# MSP432E411Y register map
Vendor: Texas Instruments; Series: MSP432E4; File version: 3.200
CPU: CM4 r1p2, little endian, no MPU, FPU, 3 interrupt priority bits
Registers are 32-bit, read-write, no defined reset value unless marked. A register's access mark holds for its fields unless they carry their own. Offsets are from the block's base; [hi:lo] are bit positions.

## I2C0 — Register map for I2C0 peripheral
Base 0x40020000; register names take the prefix I2C0
Same registers: I2C1 0x40021000 (register names take the prefix I2C1), I2C2 0x40022000 (register names take the prefix I2C2), I2C3 0x40023000 (register names take the prefix I2C3), I2C8 0x400B8000 (register names take the prefix I2C8), I2C9 0x400B9000 (register names take the prefix I2C9), I2C4 0x400C0000 (register names take the prefix I2C4), I2C5 0x400C1000 (register names take the prefix I2C5), I2C6 0x400C2000 (register names take the prefix I2C6), I2C7 0x400C3000 (register names take the prefix I2C7)
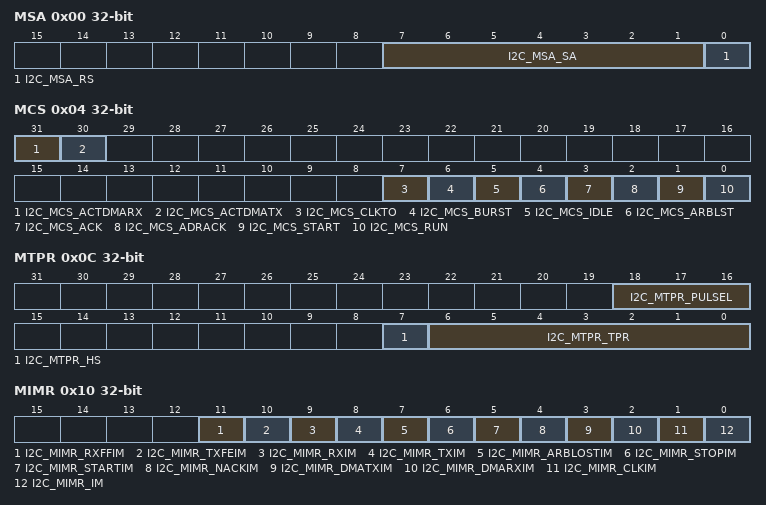
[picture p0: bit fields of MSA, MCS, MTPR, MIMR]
0x00 MSA — I2C Master Slave Address
  [7:1] I2C_MSA_SA — I2C Slave Address
  [0] I2C_MSA_RS — Receive not send
0x04 MCS — I2C Master Control/Status
  [31] I2C_MCS_ACTDMARX — DMA RX Active Status
  [30] I2C_MCS_ACTDMATX — DMA TX Active Status
  [7] I2C_MCS_CLKTO — Clock Timeout Error
  [6] I2C_MCS_BURST — Burst Enable
  [5] I2C_MCS_IDLE — I2C Idle
  [4] I2C_MCS_ARBLST — Arbitration Lost
  [3] I2C_MCS_ACK — Data Acknowledge Enable
  [2] I2C_MCS_ADRACK — Acknowledge Address
  [1] I2C_MCS_START — Generate START
  [0] I2C_MCS_RUN — I2C Master Enable
0x04 MCS (I2C0_ALT view) — I2C Master Control/Status
  [6] I2C_MCS_BUSBSY — Bus Busy
  [5] I2C_MCS_QCMD — Quick Command
  [4] I2C_MCS_HS — High-Speed Enable
  [3] I2C_MCS_DATACK — Acknowledge Data
  [2] I2C_MCS_STOP — Generate STOP
  [1] I2C_MCS_ERROR — Error
  [0] I2C_MCS_BUSY — I2C Busy
0x08 MDR — I2C Master Data
  [7:0] I2C_MDR_DATA — This byte contains the data transferred during a transaction
0x0C MTPR — I2C Master Timer Period
  [18:16] I2C_MTPR_PULSEL — Glitch Suppression Pulse Width
    0=I2C_MTPR_PULSEL_BYPASS (Bypass); 1=1 clock; 2=2 clocks; 3=3 clocks; 4=4 clocks; 5=8 clocks; 6=16 clocks; 7=31 clocks
  [7] I2C_MTPR_HS — High-Speed Enable
  [6:0] I2C_MTPR_TPR — Timer Period
0x10 MIMR — I2C Master Interrupt Mask
  [11] I2C_MIMR_RXFFIM — Receive FIFO Full Interrupt Mask
  [10] I2C_MIMR_TXFEIM — Transmit FIFO Empty Interrupt Mask
  [9] I2C_MIMR_RXIM — Receive FIFO Request Interrupt Mask
  [8] I2C_MIMR_TXIM — Transmit FIFO Request Interrupt Mask
  [7] I2C_MIMR_ARBLOSTIM — Arbitration Lost Interrupt Mask
  [6] I2C_MIMR_STOPIM — STOP Detection Interrupt Mask
  [5] I2C_MIMR_STARTIM — START Detection Interrupt Mask
  [4] I2C_MIMR_NACKIM — Address/Data NACK Interrupt Mask
  [3] I2C_MIMR_DMATXIM — Transmit DMA Interrupt Mask
  [2] I2C_MIMR_DMARXIM — Receive DMA Interrupt Mask
  [1] I2C_MIMR_CLKIM — Clock Timeout Interrupt Mask
  [0] I2C_MIMR_IM — Master Interrupt Mask
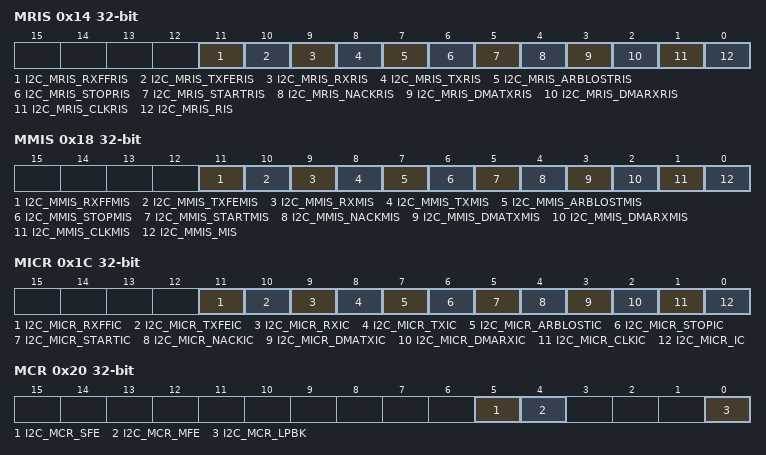
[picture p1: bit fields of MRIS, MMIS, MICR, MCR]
0x14 MRIS — I2C Master Raw Interrupt Status
  [11] I2C_MRIS_RXFFRIS — Receive FIFO Full Raw Interrupt Status
  [10] I2C_MRIS_TXFERIS — Transmit FIFO Empty Raw Interrupt Status
  [9] I2C_MRIS_RXRIS — Receive FIFO Request Raw Interrupt Status
  [8] I2C_MRIS_TXRIS — Transmit Request Raw Interrupt Status
  [7] I2C_MRIS_ARBLOSTRIS — Arbitration Lost Raw Interrupt Status
  [6] I2C_MRIS_STOPRIS — STOP Detection Raw Interrupt Status
  [5] I2C_MRIS_STARTRIS — START Detection Raw Interrupt Status
  [4] I2C_MRIS_NACKRIS — Address/Data NACK Raw Interrupt Status
  [3] I2C_MRIS_DMATXRIS — Transmit DMA Raw Interrupt Status
  [2] I2C_MRIS_DMARXRIS — Receive DMA Raw Interrupt Status
  [1] I2C_MRIS_CLKRIS — Clock Timeout Raw Interrupt Status
  [0] I2C_MRIS_RIS — Master Raw Interrupt Status
0x18 MMIS — I2C Master Masked Interrupt Status
  [11] I2C_MMIS_RXFFMIS — Receive FIFO Full Interrupt Mask
  [10] I2C_MMIS_TXFEMIS — Transmit FIFO Empty Interrupt Mask
  [9] I2C_MMIS_RXMIS — Receive FIFO Request Interrupt Mask
  [8] I2C_MMIS_TXMIS — Transmit Request Interrupt Mask
  [7] I2C_MMIS_ARBLOSTMIS — Arbitration Lost Interrupt Mask
  [6] I2C_MMIS_STOPMIS — STOP Detection Interrupt Mask
  [5] I2C_MMIS_STARTMIS — START Detection Interrupt Mask
  [4] I2C_MMIS_NACKMIS — Address/Data NACK Interrupt Mask
  [3] I2C_MMIS_DMATXMIS — Transmit DMA Interrupt Status
  [2] I2C_MMIS_DMARXMIS — Receive DMA Interrupt Status
  [1] I2C_MMIS_CLKMIS — Clock Timeout Masked Interrupt Status
  [0] I2C_MMIS_MIS — Masked Interrupt Status
0x1C MICR wo — I2C Master Interrupt Clear
  [11] I2C_MICR_RXFFIC — Receive FIFO Full Interrupt Clear
  [10] I2C_MICR_TXFEIC — Transmit FIFO Empty Interrupt Clear
  [9] I2C_MICR_RXIC — Receive FIFO Request Interrupt Clear
  [8] I2C_MICR_TXIC — Transmit FIFO Request Interrupt Clear
  [7] I2C_MICR_ARBLOSTIC — Arbitration Lost Interrupt Clear
  [6] I2C_MICR_STOPIC — STOP Detection Interrupt Clear
  [5] I2C_MICR_STARTIC — START Detection Interrupt Clear
  [4] I2C_MICR_NACKIC — Address/Data NACK Interrupt Clear
  [3] I2C_MICR_DMATXIC — Transmit DMA Interrupt Clear
  [2] I2C_MICR_DMARXIC — Receive DMA Interrupt Clear
  [1] I2C_MICR_CLKIC — Clock Timeout Interrupt Clear
  [0] I2C_MICR_IC — Master Interrupt Clear
0x20 MCR — I2C Master Configuration
  [5] I2C_MCR_SFE — I2C Slave Function Enable
  [4] I2C_MCR_MFE — I2C Master Function Enable
  [0] I2C_MCR_LPBK — I2C Loopback
0x24 MCLKOCNT — I2C Master Clock Low Timeout Count
  [7:0] I2C_MCLKOCNT_CNTL — I2C Master Count
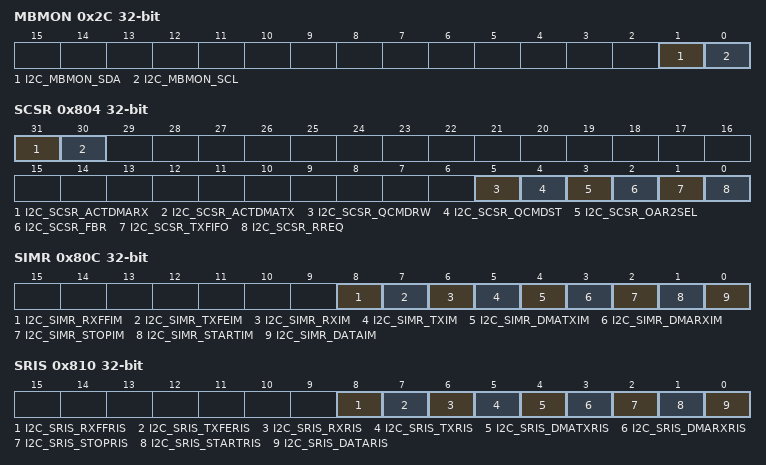
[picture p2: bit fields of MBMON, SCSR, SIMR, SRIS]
0x2C MBMON — I2C Master Bus Monitor
  [1] I2C_MBMON_SDA — I2C SDA Status
  [0] I2C_MBMON_SCL — I2C SCL Status
0x30 MBLEN — I2C Master Burst Length
  [7:0] I2C_MBLEN_CNTL — I2C Burst Length
0x34 MBCNT — I2C Master Burst Count
  [7:0] I2C_MBCNT_CNTL
0x800 SOAR — I2C Slave Own Address
  [6:0] I2C_SOAR_OAR
0x804 SCSR — I2C Slave Control/Status
  [31] I2C_SCSR_ACTDMARX — DMA RX Active Status
  [30] I2C_SCSR_ACTDMATX — DMA TX Active Status
  [5] I2C_SCSR_QCMDRW — Quick Command Read / Write
  [4] I2C_SCSR_QCMDST — Quick Command Status
  [3] I2C_SCSR_OAR2SEL — OAR2 Address Matched
  [2] I2C_SCSR_FBR — First Byte Received
  [1] I2C_SCSR_TXFIFO — TX FIFO Enable
  [0] I2C_SCSR_RREQ — Receive Request
0x804 SCSR (I2C0_ALT view) — I2C Slave Control/Status
  [2] I2C_SCSR_RXFIFO — RX FIFO Enable
  [1] I2C_SCSR_TREQ — Transmit Request
  [0] I2C_SCSR_DA — Device Active
0x808 SDR — I2C Slave Data
  [7:0] I2C_SDR_DATA — Data for Transfer
0x80C SIMR — I2C Slave Interrupt Mask
  [8] I2C_SIMR_RXFFIM — Receive FIFO Full Interrupt Mask
  [7] I2C_SIMR_TXFEIM — Transmit FIFO Empty Interrupt Mask
  [6] I2C_SIMR_RXIM — Receive FIFO Request Interrupt Mask
  [5] I2C_SIMR_TXIM — Transmit FIFO Request Interrupt Mask
  [4] I2C_SIMR_DMATXIM — Transmit DMA Interrupt Mask
  [3] I2C_SIMR_DMARXIM — Receive DMA Interrupt Mask
  [2] I2C_SIMR_STOPIM — Stop Condition Interrupt Mask
  [1] I2C_SIMR_STARTIM — Start Condition Interrupt Mask
  [0] I2C_SIMR_DATAIM — Data Interrupt Mask
0x810 SRIS — I2C Slave Raw Interrupt Status
  [8] I2C_SRIS_RXFFRIS — Receive FIFO Full Raw Interrupt Status
  [7] I2C_SRIS_TXFERIS — Transmit FIFO Empty Raw Interrupt Status
  [6] I2C_SRIS_RXRIS — Receive FIFO Request Raw Interrupt Status
  [5] I2C_SRIS_TXRIS — Transmit Request Raw Interrupt Status
  [4] I2C_SRIS_DMATXRIS — Transmit DMA Raw Interrupt Status
  [3] I2C_SRIS_DMARXRIS — Receive DMA Raw Interrupt Status
  [2] I2C_SRIS_STOPRIS — Stop Condition Raw Interrupt Status
  [1] I2C_SRIS_STARTRIS — Start Condition Raw Interrupt Status
  [0] I2C_SRIS_DATARIS — Data Raw Interrupt Status
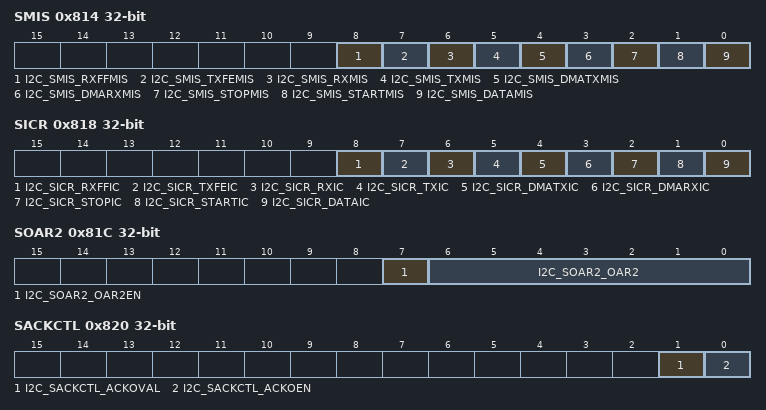
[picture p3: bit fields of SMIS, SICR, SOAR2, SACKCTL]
0x814 SMIS — I2C Slave Masked Interrupt Status
  [8] I2C_SMIS_RXFFMIS — Receive FIFO Full Interrupt Mask
  [7] I2C_SMIS_TXFEMIS — Transmit FIFO Empty Interrupt Mask
  [6] I2C_SMIS_RXMIS — Receive FIFO Request Interrupt Mask
  [5] I2C_SMIS_TXMIS — Transmit FIFO Request Interrupt Mask
  [4] I2C_SMIS_DMATXMIS — Transmit DMA Masked Interrupt Status
  [3] I2C_SMIS_DMARXMIS — Receive DMA Masked Interrupt Status
  [2] I2C_SMIS_STOPMIS — Stop Condition Masked Interrupt Status
  [1] I2C_SMIS_STARTMIS — Start Condition Masked Interrupt Status
  [0] I2C_SMIS_DATAMIS — Data Masked Interrupt Status
0x818 SICR wo — I2C Slave Interrupt Clear
  [8] I2C_SICR_RXFFIC — Receive FIFO Full Interrupt Mask
  [7] I2C_SICR_TXFEIC — Transmit FIFO Empty Interrupt Mask
  [6] I2C_SICR_RXIC — Receive Request Interrupt Mask
  [5] I2C_SICR_TXIC — Transmit Request Interrupt Mask
  [4] I2C_SICR_DMATXIC — Transmit DMA Interrupt Clear
  [3] I2C_SICR_DMARXIC — Receive DMA Interrupt Clear
  [2] I2C_SICR_STOPIC — Stop Condition Interrupt Clear
  [1] I2C_SICR_STARTIC — Start Condition Interrupt Clear
  [0] I2C_SICR_DATAIC — Data Interrupt Clear
0x81C SOAR2 — I2C Slave Own Address 2
  [7] I2C_SOAR2_OAR2EN — I2C Slave Own Address 2 Enable
  [6:0] I2C_SOAR2_OAR2 — I2C Slave Own Address 2
0x820 SACKCTL — I2C Slave ACK Control
  [1] I2C_SACKCTL_ACKOVAL — I2C Slave ACK Override Value
  [0] I2C_SACKCTL_ACKOEN — I2C Slave ACK Override Enable
0xF00 FIFODATA — I2C FIFO Data
  [7:0] I2C_FIFODATA_DATA — I2C TX FIFO Write Data Byte
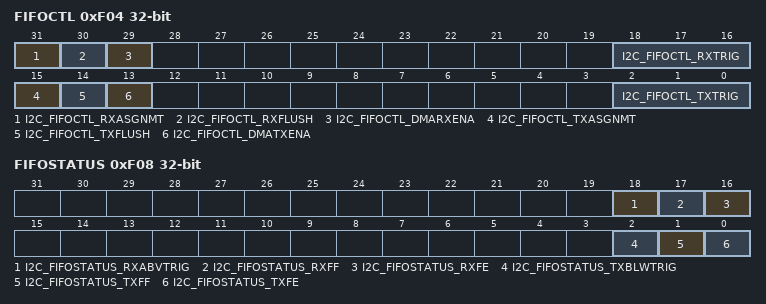
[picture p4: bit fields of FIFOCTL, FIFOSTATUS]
0xF04 FIFOCTL — I2C FIFO Control
  [31] I2C_FIFOCTL_RXASGNMT — RX Control Assignment
  [30] I2C_FIFOCTL_RXFLUSH — RX FIFO Flush
  [29] I2C_FIFOCTL_DMARXENA — DMA RX Channel Enable
  [18:16] I2C_FIFOCTL_RXTRIG — RX FIFO Trigger
  [15] I2C_FIFOCTL_TXASGNMT — TX Control Assignment
  [14] I2C_FIFOCTL_TXFLUSH — TX FIFO Flush
  [13] I2C_FIFOCTL_DMATXENA — DMA TX Channel Enable
  [2:0] I2C_FIFOCTL_TXTRIG — TX FIFO Trigger
0xF08 FIFOSTATUS — I2C FIFO Status
  [18] I2C_FIFOSTATUS_RXABVTRIG — RX FIFO Above Trigger Level
  [17] I2C_FIFOSTATUS_RXFF — RX FIFO Full
  [16] I2C_FIFOSTATUS_RXFE — RX FIFO Empty
  [2] I2C_FIFOSTATUS_TXBLWTRIG — TX FIFO Below Trigger Level
  [1] I2C_FIFOSTATUS_TXFF — TX FIFO Full
  [0] I2C_FIFOSTATUS_TXFE — TX FIFO Empty
0xFC0 PP — I2C Peripheral Properties
  [0] I2C_PP_HS — High-Speed Capable
0xFC4 PC — I2C Peripheral Configuration
  [0] I2C_PC_HS — High-Speed Capable

## Notices in the file
Software License Agreement
Texas Instruments (TI) is supplying this software for use solely and
exclusively on TI's microcontroller products. The software is owned by
TI and/or its suppliers, and is protected under applicable copyright
laws. You may not combine this software with "viral" open-source
software in order to form a larger program.
THIS SOFTWARE IS PROVIDED "AS IS" AND WITH ALL FAULTS.
NO WARRANTIES, WHETHER EXPRESS, IMPLIED OR STATUTORY, INCLUDING, BUT
NOT LIMITED TO, IMPLIED WARRANTIES OF MERCHANTABILITY AND FITNESS FOR
A PARTICULAR PURPOSE APPLY TO THIS SOFTWARE. TI SHALL NOT, UNDER ANY
CIRCUMSTANCES, BE LIABLE FOR SPECIAL, INCIDENTAL, OR CONSEQUENTIAL
DAMAGES, FOR ANY REASON WHATSOEVER.
